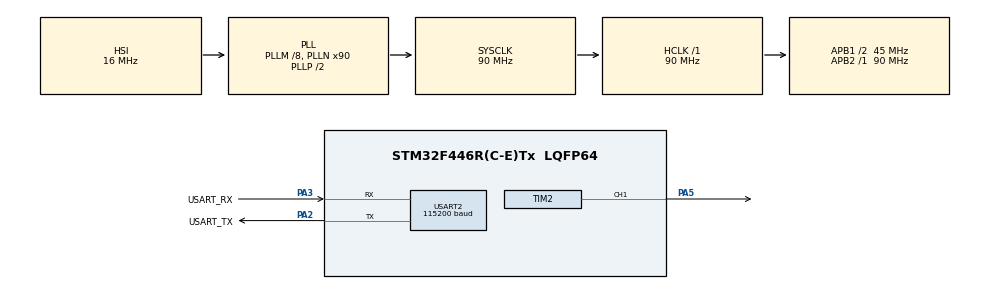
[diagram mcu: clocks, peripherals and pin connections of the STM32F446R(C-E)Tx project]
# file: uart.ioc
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Mcu.Family=STM32F4
Mcu.Name=STM32F446R(C-E)Tx
Mcu.Package=LQFP64
NVIC.PriorityGroup=NVIC_PRIORITYGROUP_1
NVIC.TIM7_IRQn=true\:1\:0\:true\:false\:true\:true\:true\:true
NVIC.USART2_IRQn=true\:0\:0\:true\:false\:true\:true\:true\:true
PA13.GPIO_Label=TMS
PA13.Mode=Serial_Wire
PA13.Signal=SYS_JTMS-SWDIO
PA14.GPIO_Label=TCK
PA14.Mode=Serial_Wire
PA14.Signal=SYS_JTCK-SWCLK
PA2.GPIO_Label=USART_TX
PA2.Mode=Asynchronous
PA2.Signal=USART2_TX
PA3.GPIO_Label=USART_RX
PA3.Mode=Asynchronous
PA3.Signal=USART2_RX
PA5.Signal=S_TIM2_CH1_ETR
PB3.GPIO_Label=SWO
PB3.Signal=SYS_JTDO-SWO
PC14-OSC32_IN.Mode=LSE-External-Oscillator
PC14-OSC32_IN.Signal=RCC_OSC32_IN
PC15-OSC32_OUT.Mode=LSE-External-Oscillator
PC15-OSC32_OUT.Signal=RCC_OSC32_OUT
PH0-OSC_IN.Mode=HSE-External-Oscillator
PH0-OSC_IN.Signal=RCC_OSC_IN
PH1-OSC_OUT.Mode=HSE-External-Oscillator
PH1-OSC_OUT.Signal=RCC_OSC_OUT
ProjectManager.HeapSize=0x200
ProjectManager.StackSize=0x400
ProjectManager.TargetToolchain=STM32CubeIDE
RCC.48MHZClocksFreq_Value=84000000
RCC.AHBFreq_Value=90000000
RCC.APB1CLKDivider=RCC_HCLK_DIV2
RCC.APB1Freq_Value=45000000
RCC.APB1TimFreq_Value=90000000
RCC.APB2Freq_Value=90000000
RCC.APB2TimFreq_Value=90000000
RCC.CortexFreq_Value=90000000
RCC.FLatency-AdvancedSettings=FLASH_LATENCY_2
RCC.HCLKFreq_Value=90000000
RCC.HSE_VALUE=8000000
RCC.HSI_VALUE=16000000
RCC.PLLM=8
RCC.PLLN=90
RCC.SYSCLKFreq_VALUE=90000000
RCC.SYSCLKSource=RCC_SYSCLKSOURCE_PLLCLK
RCC.USBFreq_Value=90000000
RCC.VCOOutputFreq_Value=180000000
SH.S_TIM2_CH1_ETR.0=TIM2_CH1,PWM Generation1 CH1
TIM2.Channel-PWM\ Generation1\ CH1=TIM_CHANNEL_1
TIM2.Period=999
TIM2.Prescaler=89
TIM7.Period=9999
TIM7.Prescaler=89
USART2.BaudRate=115200
USART2.VirtualMode=VM_ASYNC
VP_TIM2_VS_ClockSourceINT.Mode=Internal
VP_TIM7_VS_ClockSourceINT.Mode=Enable_Timer
board=NUCLEO-F446RE

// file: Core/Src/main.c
/* USER CODE BEGIN Header */
/**
  ******************************************************************************
  * @file           : main.c
  * @brief          : Main program body
  ******************************************************************************
  * @attention
  *
  * Copyright (c) 2025 STMicroelectronics.
  * All rights reserved.
  *
  * This software is licensed under terms that can be found in the LICENSE file
  * in the root directory of this software component.
  * If no LICENSE file comes with this software, it is provided AS-IS.
  *
  ******************************************************************************
  */
/* USER CODE END Header */
#include "main.h"

/* USER CODE BEGIN Includes */
#include "string.h"
#include "stdlib.h"
#include <stdio.h>
/* USER CODE END Includes */

TIM_HandleTypeDef htim2;
TIM_HandleTypeDef htim7;

UART_HandleTypeDef huart2;

void SystemClock_Config(void);
static void MX_GPIO_Init(void);
static void MX_USART2_UART_Init(void);
static void MX_TIM7_Init(void);
static void MX_TIM2_Init(void);
/* USER CODE BEGIN PFP */
uint8_t Data; //INCOMING DATA
char data[255] = {0}; // THE SENTENCE
volatile uint8_t idx = 0; // IDX IN SENTENCE
volatile uint8_t state = 0; // IN OR OUT OF MAIN
volatile uint16_t tp = 0; // TIME PERIOD
volatile uint16_t tp_cnt= 0; //TP COUNT
char err[] = "\r\nError: Unknown command Type HELP\r\n>";
char cmd[] = "\r\nCommands:\r\nSET PWM <10,20,..,100>   - Set LED brightness %\r\nSET BLINK <ms>           - Blink LED with period(10-2000) in ms\r\nSTATUS                   - Show system status\r\nIDLE                     - Set to idle mode\r\n>";
void HAL_UART_RxCpltCallback(UART_HandleTypeDef *huart){
	data[idx] = Data;
	idx++;
	if(Data == '\r' || Data == '\n') {
		state |= 1<<1;
		data[idx] = '\0';
	}
	else {
		HAL_UART_Transmit(&huart2,&Data,1,1);
		HAL_UART_Receive_IT(&huart2,&Data,1);
	}

}
void HAL_TIM_PeriodElapsedCallback(TIM_HandleTypeDef *htim){
	++tp_cnt;
	if(htim->Instance == TIM7 && tp_cnt >= (tp/10)){
		HAL_GPIO_TogglePin(GPIOA,GPIO_PIN_5);
		tp_cnt = 0;
	}
}
/* USER CODE END PFP */

/* USER CODE BEGIN 0 */

// This function acts as the "driver" for printf

/* USER CODE END 0 */

int main(void)
{

  /* MCU Configuration--------------------------------------------------------*/

  /* Reset of all peripherals, Initializes the Flash interface and the Systick. */
  HAL_Init();

  /* Configure the system clock */
  SystemClock_Config();

  /* Initialize all configured peripherals */
  MX_GPIO_Init();
  MX_USART2_UART_Init();
  MX_TIM7_Init();
  MX_TIM2_Init();

  /* Infinite loop */
  /* USER CODE BEGIN WHILE */
  volatile uint8_t dc = 0;

  char msg[] = "\r\n===== STM32 CLI Ready =====\r\nType HELP for commands\r\n>";
    char status[50] ;
    while (1)
    {
    	if(state == 0){
    	    		HAL_UART_Transmit(&huart2,(uint8_t*)msg,strlen(msg),10);
    	    		state |= 1;
    	    	}
    	if(state & 1<<1){
    	    		//check for help
    				if( idx == 5 && strncmp(data,"HELP",4) == 0	){
    	    						HAL_UART_Transmit(&huart2,(uint8_t*)cmd,strlen(cmd),25);
    	    						snprintf(status,25, "\r\nMode : Idle\r\n>");
    	    				}
    	    				//check for PWM
    	    				else if(strncmp(data,"SET PWM ",8) == 0){
    	    					dc = (atoi((char*)data + 8))	;
    	    					if((dc % 10 !=0) || dc < 0 || dc > 100){
    	    						HAL_UART_Transmit(&huart2,(uint8_t*)"\r\nwrong values\r\n >",16,3);
    	    					}
    	    					else{
    	    						if(HAL_TIM_Base_GetState(&htim7) == HAL_TIM_STATE_BUSY){
    	    							HAL_TIM_Base_Stop(&htim7);
    	    						}
    	    						GPIO_InitTypeDef GPIO_InitStruct = {0};
    	    						GPIO_InitStruct.Pin = GPIO_PIN_5;
    	    						GPIO_InitStruct.Mode = GPIO_MODE_AF_PP;
    	    							GPIO_InitStruct.Speed = GPIO_SPEED_FREQ_LOW;
    	    							GPIO_InitStruct.Alternate = GPIO_AF1_TIM2;
    	    							HAL_GPIO_Init(GPIOA, &GPIO_InitStruct);
    	    						HAL_TIM_PWM_Start(&htim2,TIM_CHANNEL_1);
    	    						__HAL_TIM_SET_COMPARE(&htim2,TIM_CHANNEL_1,(dc*999)/100);
    	    						char pwm_state[] = "\r\nDone!:)\r\n>";
    	    						snprintf(status,50, "\r\nMode      : PWM\r\nPWM Level : %d%%\r\n>",dc);
    	    						HAL_UART_Transmit(&huart2,(uint8_t*)pwm_state,strlen(pwm_state),1);
    	    					}
    	    				}
    	    				//blink
    	    				else if(!strncmp(data,"SET BLINK ",10)){
    	    					tp = atoi((char*)data + 10);
    	    					if(tp < 10 || tp >2000){
    	    					    	   HAL_UART_Transmit(&huart2,(uint8_t*)"\r\nwrong values\r\n >",16,3);
    	    					}else{
    	    						if(HAL_TIM_PWM_GetState(&htim2) == HAL_TIM_STATE_BUSY){
    	    							HAL_TIM_PWM_Stop(&htim2,TIM_CHANNEL_1);
    	    						}
    	    						 GPIO_InitTypeDef GPIO_InitStruct = {0};
    	    						 GPIO_InitStruct.Pin = GPIO_PIN_5;
    	    						 GPIO_InitStruct.Mode = GPIO_MODE_OUTPUT_PP;
    	    						 GPIO_InitStruct.Pull = GPIO_NOPULL;
    	    						 GPIO_InitStruct.Speed = GPIO_SPEED_FREQ_LOW;
    	    						 HAL_GPIO_Init(GPIOA, &GPIO_InitStruct);
    	    						__HAL_TIM_SET_COUNTER(&htim7, 0);
    	    						tp_cnt = 0;
    	    						HAL_TIM_Base_Start_IT(&htim7);
    	    						snprintf(status,50, "\r\nMode        : Blink\r\nTime Period : %dms\r\n>",tp);
    	    						HAL_UART_Transmit(&huart2,(uint8_t*)"\r\nDONE\r\n>",9,2);
    	    					}
    	    				}
    	    				else if(!strncmp(data,"STATUS",6) && idx == 7){
    	    					HAL_UART_Transmit(&huart2,(uint8_t*)status,strlen(status),20);
    	    				}
    	    				else if(!strncmp(data,"IDLE",4) && idx == 5){
    	    					if(HAL_TIM_PWM_GetState(&htim2) == HAL_TIM_STATE_BUSY){
    	    						HAL_TIM_PWM_Stop(&htim2,TIM_CHANNEL_1);
    	    					}
    	    					if(HAL_TIM_Base_GetState(&htim7) == HAL_TIM_STATE_BUSY){
    	    						HAL_TIM_Base_Stop(&htim7);
    	    						HAL_GPIO_WritePin(GPIOA,GPIO_PIN_5,GPIO_PIN_RESET);
    	    					}
    	    					HAL_UART_Transmit(&huart2,(uint8_t*)"\r\nMade LED Off\r\n",18,2);
    	    					snprintf(status,25, "\r\nMode : Idle\r\n>");
    	    				}
    	    				else{
    	    						HAL_UART_Transmit(&huart2,(uint8_t*)err,strlen(err),5);
    	    				}
    	    				state &= ~(1<<1);
    	    				idx=0;

    	    	}

    /* USER CODE END WHILE */

    /* USER CODE BEGIN 3 */
    	HAL_UART_Receive_IT(&huart2,&Data,1);
    }
  /* USER CODE END 3 */
}

void SystemClock_Config(void)
{
  RCC_OscInitTypeDef RCC_OscInitStruct = {0};
  RCC_ClkInitTypeDef RCC_ClkInitStruct = {0};

  /** Configure the main internal regulator output voltage
  */
  __HAL_RCC_PWR_CLK_ENABLE();
  __HAL_PWR_VOLTAGESCALING_CONFIG(PWR_REGULATOR_VOLTAGE_SCALE3);

  /** Initializes the RCC Oscillators according to the specified parameters
  * in the RCC_OscInitTypeDef structure.
  */
  RCC_OscInitStruct.OscillatorType = RCC_OSCILLATORTYPE_HSI;
  RCC_OscInitStruct.HSIState = RCC_HSI_ON;
  RCC_OscInitStruct.HSICalibrationValue = RCC_HSICALIBRATION_DEFAULT;
  RCC_OscInitStruct.PLL.PLLState = RCC_PLL_ON;
  RCC_OscInitStruct.PLL.PLLSource = RCC_PLLSOURCE_HSI;
  RCC_OscInitStruct.PLL.PLLM = 8;
  RCC_OscInitStruct.PLL.PLLN = 90;
  RCC_OscInitStruct.PLL.PLLP = RCC_PLLP_DIV2;
  RCC_OscInitStruct.PLL.PLLQ = 2;
  RCC_OscInitStruct.PLL.PLLR = 2;
  if (HAL_RCC_OscConfig(&RCC_OscInitStruct) != HAL_OK)
  {
    Error_Handler();
  }

  /** Initializes the CPU, AHB and APB buses clocks
  */
  RCC_ClkInitStruct.ClockType = RCC_CLOCKTYPE_HCLK|RCC_CLOCKTYPE_SYSCLK
                              |RCC_CLOCKTYPE_PCLK1|RCC_CLOCKTYPE_PCLK2;
  RCC_ClkInitStruct.SYSCLKSource = RCC_SYSCLKSOURCE_PLLCLK;
  RCC_ClkInitStruct.AHBCLKDivider = RCC_SYSCLK_DIV1;
  RCC_ClkInitStruct.APB1CLKDivider = RCC_HCLK_DIV2;
  RCC_ClkInitStruct.APB2CLKDivider = RCC_HCLK_DIV1;

  if (HAL_RCC_ClockConfig(&RCC_ClkInitStruct, FLASH_LATENCY_2) != HAL_OK)
  {
    Error_Handler();
  }
}

static void MX_TIM2_Init(void)
{

  TIM_ClockConfigTypeDef sClockSourceConfig = {0};
  TIM_MasterConfigTypeDef sMasterConfig = {0};
  TIM_OC_InitTypeDef sConfigOC = {0};

  htim2.Instance = TIM2;
  htim2.Init.Prescaler = 89;
  htim2.Init.CounterMode = TIM_COUNTERMODE_UP;
  htim2.Init.Period = 999;
  htim2.Init.ClockDivision = TIM_CLOCKDIVISION_DIV1;
  htim2.Init.AutoReloadPreload = TIM_AUTORELOAD_PRELOAD_DISABLE;
  if (HAL_TIM_Base_Init(&htim2) != HAL_OK)
  {
    Error_Handler();
  }
  sClockSourceConfig.ClockSource = TIM_CLOCKSOURCE_INTERNAL;
  if (HAL_TIM_ConfigClockSource(&htim2, &sClockSourceConfig) != HAL_OK)
  {
    Error_Handler();
  }
  if (HAL_TIM_PWM_Init(&htim2) != HAL_OK)
  {
    Error_Handler();
  }
  sMasterConfig.MasterOutputTrigger = TIM_TRGO_RESET;
  sMasterConfig.MasterSlaveMode = TIM_MASTERSLAVEMODE_DISABLE;
  if (HAL_TIMEx_MasterConfigSynchronization(&htim2, &sMasterConfig) != HAL_OK)
  {
    Error_Handler();
  }
  sConfigOC.OCMode = TIM_OCMODE_PWM1;
  sConfigOC.Pulse = 0;
  sConfigOC.OCPolarity = TIM_OCPOLARITY_HIGH;
  sConfigOC.OCFastMode = TIM_OCFAST_DISABLE;
  if (HAL_TIM_PWM_ConfigChannel(&htim2, &sConfigOC, TIM_CHANNEL_1) != HAL_OK)
  {
    Error_Handler();
  }
  HAL_TIM_MspPostInit(&htim2);

}

static void MX_TIM7_Init(void)
{

  TIM_MasterConfigTypeDef sMasterConfig = {0};

  htim7.Instance = TIM7;
  htim7.Init.Prescaler = 89;
  htim7.Init.CounterMode = TIM_COUNTERMODE_UP;
  htim7.Init.Period = 9999;
  htim7.Init.AutoReloadPreload = TIM_AUTORELOAD_PRELOAD_DISABLE;
  if (HAL_TIM_Base_Init(&htim7) != HAL_OK)
  {
    Error_Handler();
  }
  sMasterConfig.MasterOutputTrigger = TIM_TRGO_RESET;
  sMasterConfig.MasterSlaveMode = TIM_MASTERSLAVEMODE_DISABLE;
  if (HAL_TIMEx_MasterConfigSynchronization(&htim7, &sMasterConfig) != HAL_OK)
  {
    Error_Handler();
  }

}

static void MX_USART2_UART_Init(void)
{

  huart2.Instance = USART2;
  huart2.Init.BaudRate = 115200;
  huart2.Init.WordLength = UART_WORDLENGTH_8B;
  huart2.Init.StopBits = UART_STOPBITS_1;
  huart2.Init.Parity = UART_PARITY_NONE;
  huart2.Init.Mode = UART_MODE_TX_RX;
  huart2.Init.HwFlowCtl = UART_HWCONTROL_NONE;
  huart2.Init.OverSampling = UART_OVERSAMPLING_16;
  if (HAL_UART_Init(&huart2) != HAL_OK)
  {
    Error_Handler();
  }

}

static void MX_GPIO_Init(void)
{

  /* GPIO Ports Clock Enable */
  __HAL_RCC_GPIOC_CLK_ENABLE();
  __HAL_RCC_GPIOH_CLK_ENABLE();
  __HAL_RCC_GPIOA_CLK_ENABLE();
  __HAL_RCC_GPIOB_CLK_ENABLE();

}

void Error_Handler(void)
{
  __disable_irq();
  while (1)
  {
  }
}
